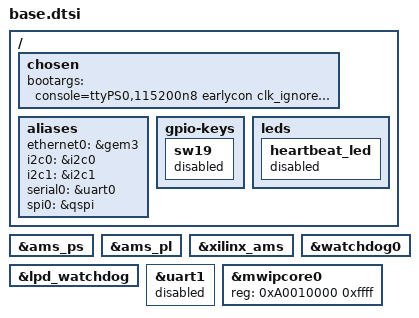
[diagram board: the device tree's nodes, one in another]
#include "zynqmp-zcu216-revA.dts"
#include "zynqmp-mw-fpga-bridge-common.dtsi"
#include "zynqmp-mw-common.dtsi"
#include "mw-aximm-common.dtsi"

/ {
	chosen {
        bootargs = "console=ttyPS0,115200n8 earlycon clk_ignore_unused initcall_blacklist=si570_driver_init debug root=/dev/ram rw cma=1700M cpuidle.off=1";
	};

     aliases {
               ethernet0 = &gem3;
               i2c0 = &i2c0;
               i2c1 = &i2c1;
               serial0 = &uart0;
               spi0 = &qspi;
               /delete-property/ gpio0;
     };

    gpio-keys {
        sw19 {
            status = "disabled";
        };
    };
    leds {
        heartbeat_led {
            status = "disabled";
        };
    };
    

     
};

&ams_ps 
{
    status = "okay";
};
&ams_pl 
{
    status = "okay";
};
&xilinx_ams 
{
    status = "okay";
};
&watchdog0 
{
    status = "okay";
};
&lpd_watchdog 
{
    status = "okay";
};

&uart1
{
    status = "disabled";
};
&mwipcore0 {
	reg = <0xA0010000 0xffff>;
};
